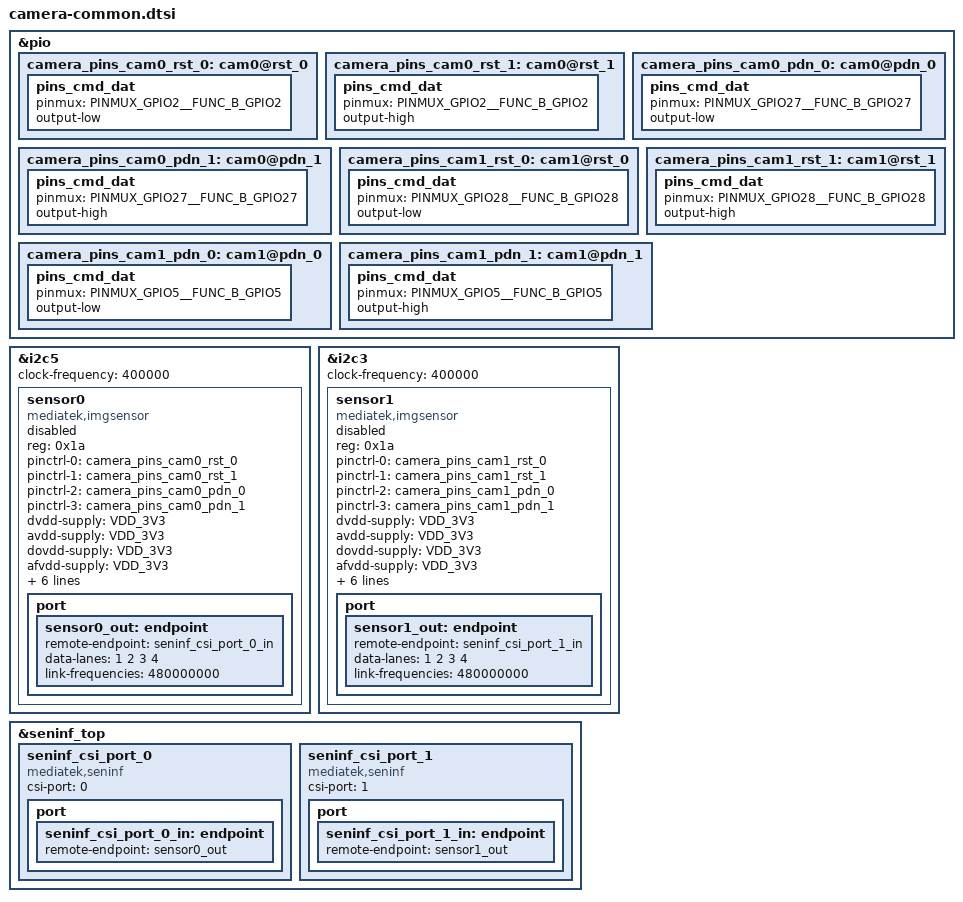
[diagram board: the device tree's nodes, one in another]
// SPDX-License-Identifier: GPL-2.0
/*
 * Copyright (c) 2024 MediaTek Inc.
 *
 */

#include <dt-bindings/clock/mediatek,mt8188-clk.h>
#include <dt-bindings/gpio/gpio.h>
#include <dt-bindings/pinctrl/mediatek,mt8188-pinfunc.h>

#include "isp71.dtsi"
#include "mtk-camera.dtsi"

/ {
	fragment@4 {
		target = <&pio>;
		__overlay__ {
			camera_pins_cam0_rst_0: cam0@rst_0 {
				pins_cmd_dat {
					pinmux = <PINMUX_GPIO2__FUNC_B_GPIO2>;
					output-low;
				};
			};
			camera_pins_cam0_rst_1: cam0@rst_1 {
				pins_cmd_dat {
					pinmux = <PINMUX_GPIO2__FUNC_B_GPIO2>;
					output-high;
				};
			};
			camera_pins_cam0_pdn_0: cam0@pdn_0 {
				pins_cmd_dat {
					pinmux = <PINMUX_GPIO27__FUNC_B_GPIO27>;
					output-low;
				};
			};
			camera_pins_cam0_pdn_1: cam0@pdn_1 {
				pins_cmd_dat {
					pinmux = <PINMUX_GPIO27__FUNC_B_GPIO27>;
					output-high;
				};
			};
			camera_pins_cam1_rst_0: cam1@rst_0 {
				pins_cmd_dat {
					pinmux = <PINMUX_GPIO28__FUNC_B_GPIO28>;
					output-low;
				};
			};
			camera_pins_cam1_rst_1: cam1@rst_1 {
				pins_cmd_dat {
					pinmux = <PINMUX_GPIO28__FUNC_B_GPIO28>;
					output-high;
				};
			};
			camera_pins_cam1_pdn_0: cam1@pdn_0 {
				pins_cmd_dat {
					pinmux = <PINMUX_GPIO5__FUNC_B_GPIO5>;
					output-low;
				};
			};
			camera_pins_cam1_pdn_1: cam1@pdn_1 {
				pins_cmd_dat {
					pinmux = <PINMUX_GPIO5__FUNC_B_GPIO5>;
					output-high;
				};
			};
		};
	};

	fragment@5 {
		target = <&i2c5>;
		__overlay__ {
			clock-frequency = <400000>;

			sensor0 {
				compatible = "mediatek,imgsensor";
				reg = <0x1a>;
				status = "disabled";

				pinctrl-names = "rst_low",
						"rst_high",
						"pdn_low",
						"pdn_high";
				pinctrl-0 = <&camera_pins_cam0_rst_0>;
				pinctrl-1 = <&camera_pins_cam0_rst_1>;
				pinctrl-2 = <&camera_pins_cam0_pdn_0>;
				pinctrl-3 = <&camera_pins_cam0_pdn_1>;
				dvdd-supply = <&VDD_3V3>;
				avdd-supply = <&VDD_3V3>;
				dovdd-supply = <&VDD_3V3>;
				afvdd-supply = <&VDD_3V3>;

				clocks = <&topckgen CLK_TOP_UNIVPLL_192M_D32>,
					<&topckgen CLK_TOP_UNIVPLL_192M_D16>,
					<&clk13m>,
					<&topckgen CLK_TOP_UNIVPLL_192M_D8>,
					<&clk26m>,
					<&topckgen CLK_TOP_UNIVPLL_192M_D4>,
					<&topckgen CLK_TOP_UNIVPLL_D6_D8>,
					<&topckgen CLK_TOP_CAMTG>;
				clock-names = "6", "12", "13", "24", "26", "48", "52", "mclk";

				port {
					sensor0_out: endpoint {
						remote-endpoint = <&seninf_csi_port_0_in>;
						data-lanes = <1 2 3 4>;
						link-frequencies = /bits/ 64 <480000000>;
					};
				};
			};
		};
	};

	fragment@6 {
		target = <&i2c3>;
		__overlay__ {
			clock-frequency = <400000>;

			sensor1 {
				compatible = "mediatek,imgsensor";
				reg = <0x1a>;
				status = "disabled";

				pinctrl-names = "rst_low",
						"rst_high",
						"pdn_low",
						"pdn_high";
				pinctrl-0 = <&camera_pins_cam1_rst_0>;
				pinctrl-1 = <&camera_pins_cam1_rst_1>;
				pinctrl-2 = <&camera_pins_cam1_pdn_0>;
				pinctrl-3 = <&camera_pins_cam1_pdn_1>;
				dvdd-supply = <&VDD_3V3>;
				avdd-supply = <&VDD_3V3>;
				dovdd-supply = <&VDD_3V3>;
				afvdd-supply = <&VDD_3V3>;

				clocks = <&topckgen CLK_TOP_UNIVPLL_192M_D32>,
					<&topckgen CLK_TOP_UNIVPLL_192M_D16>,
					<&clk13m>,
					<&topckgen CLK_TOP_UNIVPLL_192M_D8>,
					<&clk26m>,
					<&topckgen CLK_TOP_UNIVPLL_192M_D4>,
					<&topckgen CLK_TOP_UNIVPLL_D6_D8>,
					<&topckgen CLK_TOP_CAMTG2>;
				clock-names = "6", "12", "13", "24", "26", "48", "52", "mclk";

				port {
					sensor1_out: endpoint {
						remote-endpoint = <&seninf_csi_port_1_in>;
						data-lanes = <1 2 3 4>;
						link-frequencies = /bits/ 64 <480000000>;
					};
				};
			};
		};
	};

	fragment@7 {
		target = <&seninf_top>;
		__overlay__ {
			seninf_csi_port_0: seninf_csi_port_0 {
				compatible = "mediatek,seninf";
				csi-port = "0";
				port {
					seninf_csi_port_0_in: endpoint {
						remote-endpoint = <&sensor0_out>;
					};
				};
			};
			seninf_csi_port_1: seninf_csi_port_1 {
				compatible = "mediatek,seninf";
				csi-port = "1";
				port {
					seninf_csi_port_1_in: endpoint {
						remote-endpoint = <&sensor1_out>;
					};
				};
			};
		};
	};
};
